# ECC_AGGR_ECC_AGGR_04704000h register map
Vendor: Texas Instruments
Peripheral module from a debugger description file (folder am62D).
Registers are 32-bit, access not given, reset 0x0 unless marked. A register's access mark holds for its fields unless they carry their own. Offsets are as the file gives them; lines under a group give offsets from that group; [hi:lo] are bit positions; {n}, {i} and the like mark numbered series; 'fields as' and 'values as' point back to an identical list; <NAME> marks a mode.

## ecc_aggr
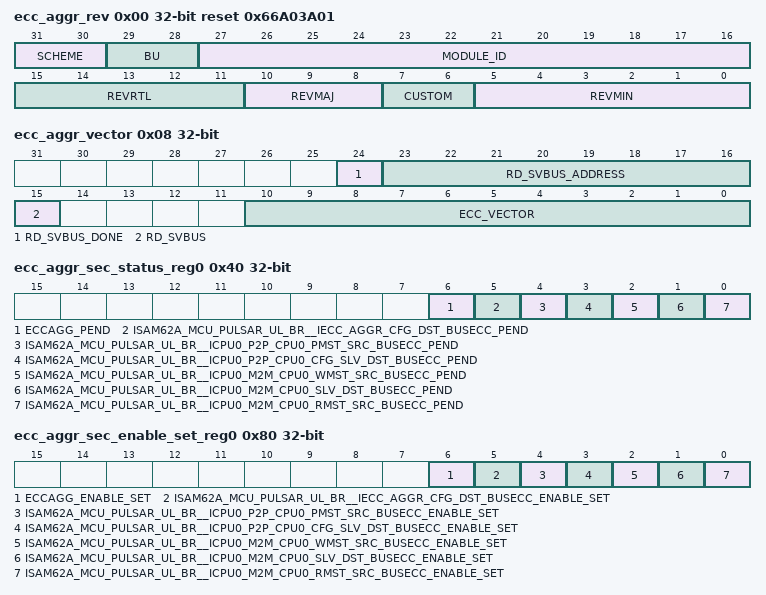
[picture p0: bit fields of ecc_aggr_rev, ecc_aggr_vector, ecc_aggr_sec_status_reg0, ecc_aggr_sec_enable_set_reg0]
0x00 ecc_aggr_rev ro reset 0x66A03A01 — Revision parameters
  [31:30] SCHEME
  [29:28] BU
  [27:16] MODULE_ID
  [15:11] REVRTL — RTL version
  [10:8] REVMAJ — Major version
  [7:6] CUSTOM — Custom version
  [5:0] REVMIN — Minor version
0x08 ecc_aggr_vector — ECC Vector Register
  [24] RD_SVBUS_DONE — Status to indicate if read on serial VBUS is complete, write of any value will clear this bit. (access R/W1TC)
  [23:16] RD_SVBUS_ADDRESS rw — Read address
  [15] RD_SVBUS — Write 1 to trigger a read on the serial VBUS (access R/W1TS)
  [10:0] ECC_VECTOR rw — Value written to select the corresponding ECC RAM for control or status
0x0C ecc_aggr_stat ro reset 0x7 — Misc Status
  [10:0] NUM_RAMS — Indicates the number of RAMS serviced by the ECC aggregator
0x10 ecc_aggr_reserved_svbus_j rw — Reference other documents that contain the ECC RAM wrapper and EDC controller serial vbus register sets.
  [31:0] DATA — Serial VBUS register data
0x3C ecc_aggr_sec_eoi_reg — EOI Register
  [0] EOI_WR — EOI Register (access R/W1TS)
0x40 ecc_aggr_sec_status_reg0 — Interrupt Status Register 0
  [6] ECCAGG_PEND — Interrupt Pending Status for eccagg_pend (access R/W1TS)
  [5] ISAM62A_MCU_PULSAR_UL_BR__IECC_AGGR_CFG_DST_BUSECC_PEND — Interrupt Pending Status for Isam62a_mcu_pulsar_ul_br__Iecc_aggr_cfg_dst_busecc_pend (access R/W1TS)
  [4] ISAM62A_MCU_PULSAR_UL_BR__ICPU0_P2P_CPU0_PMST_SRC_BUSECC_PEND — Interrupt Pending Status for Isam62a_mcu_pulsar_ul_br__Icpu0_p2p_cpu0_pmst_src_busecc_pend (access R/W1TS)
  [3] ISAM62A_MCU_PULSAR_UL_BR__ICPU0_P2P_CPU0_CFG_SLV_DST_BUSECC_PEND — Interrupt Pending Status for Isam62a_mcu_pulsar_ul_br__Icpu0_p2p_cpu0_cfg_slv_dst_busecc_pend (access R/W1TS)
  [2] ISAM62A_MCU_PULSAR_UL_BR__ICPU0_M2M_CPU0_WMST_SRC_BUSECC_PEND — Interrupt Pending Status for Isam62a_mcu_pulsar_ul_br__Icpu0_m2m_cpu0_wmst_src_busecc_pend (access R/W1TS)
  [1] ISAM62A_MCU_PULSAR_UL_BR__ICPU0_M2M_CPU0_SLV_DST_BUSECC_PEND — Interrupt Pending Status for Isam62a_mcu_pulsar_ul_br__Icpu0_m2m_cpu0_slv_dst_busecc_pend (access R/W1TS)
  [0] ISAM62A_MCU_PULSAR_UL_BR__ICPU0_M2M_CPU0_RMST_SRC_BUSECC_PEND — Interrupt Pending Status for Isam62a_mcu_pulsar_ul_br__Icpu0_m2m_cpu0_rmst_src_busecc_pend (access R/W1TS)
0x80 ecc_aggr_sec_enable_set_reg0 — Interrupt Enable Set Register 0
  [6] ECCAGG_ENABLE_SET — Interrupt Enable Set Register for eccagg_pend (access R/W1TS)
  [5] ISAM62A_MCU_PULSAR_UL_BR__IECC_AGGR_CFG_DST_BUSECC_ENABLE_SET — Interrupt Enable Set Register for Isam62a_mcu_pulsar_ul_br__Iecc_aggr_cfg_dst_busecc_pend (access R/W1TS)
  [4] ISAM62A_MCU_PULSAR_UL_BR__ICPU0_P2P_CPU0_PMST_SRC_BUSECC_ENABLE_SET — Interrupt Enable Set Register for Isam62a_mcu_pulsar_ul_br__Icpu0_p2p_cpu0_pmst_src_busecc_pend (access R/W1TS)
  [3] ISAM62A_MCU_PULSAR_UL_BR__ICPU0_P2P_CPU0_CFG_SLV_DST_BUSECC_ENABLE_SET — Interrupt Enable Set Register for Isam62a_mcu_pulsar_ul_br__Icpu0_p2p_cpu0_cfg_slv_dst_busecc_pend (access R/W1TS)
  [2] ISAM62A_MCU_PULSAR_UL_BR__ICPU0_M2M_CPU0_WMST_SRC_BUSECC_ENABLE_SET — Interrupt Enable Set Register for Isam62a_mcu_pulsar_ul_br__Icpu0_m2m_cpu0_wmst_src_busecc_pend (access R/W1TS)
  [1] ISAM62A_MCU_PULSAR_UL_BR__ICPU0_M2M_CPU0_SLV_DST_BUSECC_ENABLE_SET — Interrupt Enable Set Register for Isam62a_mcu_pulsar_ul_br__Icpu0_m2m_cpu0_slv_dst_busecc_pend (access R/W1TS)
  [0] ISAM62A_MCU_PULSAR_UL_BR__ICPU0_M2M_CPU0_RMST_SRC_BUSECC_ENABLE_SET — Interrupt Enable Set Register for Isam62a_mcu_pulsar_ul_br__Icpu0_m2m_cpu0_rmst_src_busecc_pend (access R/W1TS)
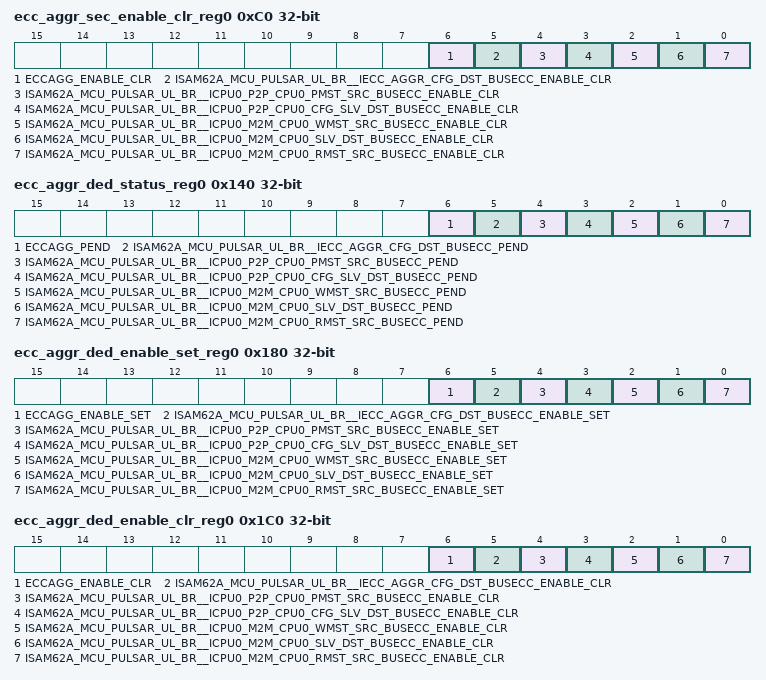
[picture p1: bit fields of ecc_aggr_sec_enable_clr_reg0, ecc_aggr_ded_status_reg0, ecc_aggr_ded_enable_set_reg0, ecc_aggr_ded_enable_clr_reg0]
0xC0 ecc_aggr_sec_enable_clr_reg0 — Interrupt Enable Clear Register 0
  [6] ECCAGG_ENABLE_CLR — Interrupt Enable Clear Register for eccagg_pend (access R/W1TC)
  [5] ISAM62A_MCU_PULSAR_UL_BR__IECC_AGGR_CFG_DST_BUSECC_ENABLE_CLR — Interrupt Enable Clear Register for Isam62a_mcu_pulsar_ul_br__Iecc_aggr_cfg_dst_busecc_pend (access R/W1TC)
  [4] ISAM62A_MCU_PULSAR_UL_BR__ICPU0_P2P_CPU0_PMST_SRC_BUSECC_ENABLE_CLR — Interrupt Enable Clear Register for Isam62a_mcu_pulsar_ul_br__Icpu0_p2p_cpu0_pmst_src_busecc_pend (access R/W1TC)
  [3] ISAM62A_MCU_PULSAR_UL_BR__ICPU0_P2P_CPU0_CFG_SLV_DST_BUSECC_ENABLE_CLR — Interrupt Enable Clear Register for Isam62a_mcu_pulsar_ul_br__Icpu0_p2p_cpu0_cfg_slv_dst_busecc_pend (access R/W1TC)
  [2] ISAM62A_MCU_PULSAR_UL_BR__ICPU0_M2M_CPU0_WMST_SRC_BUSECC_ENABLE_CLR — Interrupt Enable Clear Register for Isam62a_mcu_pulsar_ul_br__Icpu0_m2m_cpu0_wmst_src_busecc_pend (access R/W1TC)
  [1] ISAM62A_MCU_PULSAR_UL_BR__ICPU0_M2M_CPU0_SLV_DST_BUSECC_ENABLE_CLR — Interrupt Enable Clear Register for Isam62a_mcu_pulsar_ul_br__Icpu0_m2m_cpu0_slv_dst_busecc_pend (access R/W1TC)
  [0] ISAM62A_MCU_PULSAR_UL_BR__ICPU0_M2M_CPU0_RMST_SRC_BUSECC_ENABLE_CLR — Interrupt Enable Clear Register for Isam62a_mcu_pulsar_ul_br__Icpu0_m2m_cpu0_rmst_src_busecc_pend (access R/W1TC)
0x13C ecc_aggr_ded_eoi_reg — EOI Register
  [0] EOI_WR — EOI Register (access R/W1TS)
0x140 ecc_aggr_ded_status_reg0 — Interrupt Status Register 0
  fields as ecc_aggr_sec_status_reg0
0x180 ecc_aggr_ded_enable_set_reg0 — Interrupt Enable Set Register 0
  fields as ecc_aggr_sec_enable_set_reg0
0x1C0 ecc_aggr_ded_enable_clr_reg0 — Interrupt Enable Clear Register 0
  fields as ecc_aggr_sec_enable_clr_reg0
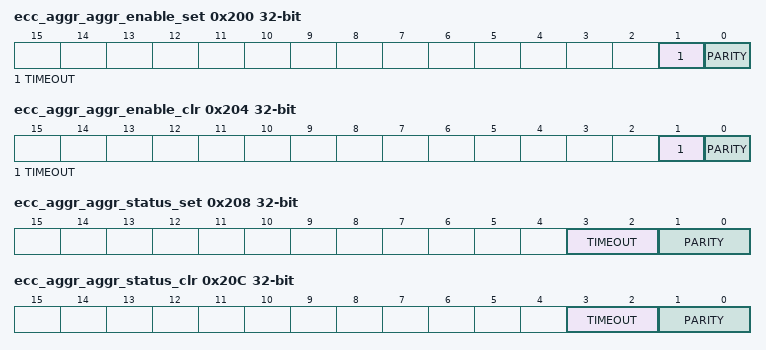
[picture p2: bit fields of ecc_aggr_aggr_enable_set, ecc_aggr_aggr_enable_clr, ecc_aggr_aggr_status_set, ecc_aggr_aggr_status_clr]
0x200 ecc_aggr_aggr_enable_set — AGGR interrupt enable set Register
  [1] TIMEOUT — interrupt enable set for svbus timeout errors (access R/W1TS)
  [0] PARITY — interrupt enable set for parity errors (access R/W1TS)
0x204 ecc_aggr_aggr_enable_clr — AGGR interrupt enable clear Register
  [1] TIMEOUT — interrupt enable clear for svbus timeout errors (access R/W1TC)
  [0] PARITY — interrupt enable clear for parity errors (access R/W1TC)
0x208 ecc_aggr_aggr_status_set — AGGR interrupt status set Register
  [3:2] TIMEOUT — interrupt status set for svbus timeout errors (access R/WI)
  [1:0] PARITY — interrupt status set for parity errors (access R/WI)
0x20C ecc_aggr_aggr_status_clr — AGGR interrupt status clear Register
  [3:2] TIMEOUT — interrupt status clear for svbus timeout errors (access R/WD)
  [1:0] PARITY — interrupt status clear for parity errors (access R/WD)
